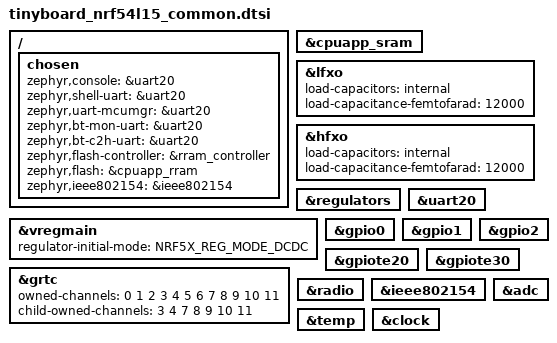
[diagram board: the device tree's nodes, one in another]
/*
 * Copyright (c) 2024 Nordic Semiconductor ASA
 *
 * SPDX-License-Identifier: Apache-2.0
 */

/* This file is common to the secure and non-secure domain */

#include "tinyboard_common.dtsi"

/ {
	chosen {
		zephyr,console = &uart20;
		zephyr,shell-uart = &uart20;
		zephyr,uart-mcumgr = &uart20;
		zephyr,bt-mon-uart = &uart20;
		zephyr,bt-c2h-uart = &uart20;
		zephyr,flash-controller = &rram_controller;
		zephyr,flash = &cpuapp_rram;
		zephyr,ieee802154 = &ieee802154;
	};
};

&cpuapp_sram {
	status = "okay";
};

&lfxo {
	load-capacitors = "internal";
	load-capacitance-femtofarad = <12000>;
};

&hfxo {
	load-capacitors = "internal";
	load-capacitance-femtofarad = <12000>;
};

&regulators {
	status = "okay";
};

&vregmain {
	status = "okay";
	regulator-initial-mode = <NRF5X_REG_MODE_DCDC>;
};

&grtc {
	owned-channels = <0 1 2 3 4 5 6 7 8 9 10 11>;
	/* Channels 7-11 reserved for Zero Latency IRQs, 3-4 for FLPR */
	child-owned-channels = <3 4 7 8 9 10 11>;
	status = "okay";
};

&uart20 {
	status = "okay";
};

&gpio0 {
	status = "okay";
};

&gpio1 {
	status = "okay";
};

&gpio2 {
	status = "okay";
};

&gpiote20 {
	status = "okay";
};

&gpiote30 {
	status = "okay";
};

&radio {
	status = "okay";
};

&ieee802154 {
	status = "okay";
};

&temp {
	status = "okay";
};

&clock {
	status = "okay";
};

&adc {
	status = "okay";
};
